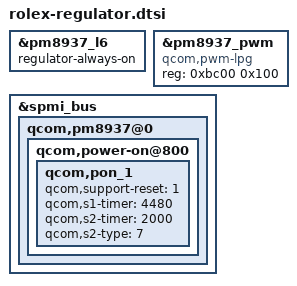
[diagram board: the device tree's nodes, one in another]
/*
 * Copyright (c) 2016, The Linux Foundation. All rights reserved.
 *
 * This program is free software; you can redistribute it and/or modify
 * it under the terms of the GNU General Public License version 2 and
 * only version 2 as published by the Free Software Foundation.
 *
 * This program is distributed in the hope that it will be useful,
 * but WITHOUT ANY WARRANTY; without even the implied warranty of
 * MERCHANTABILITY or FITNESS FOR A PARTICULAR PURPOSE.  See the
 * GNU General Public License for more details.
 */

/* msm8917-pmi8937-qrd-sku5 */
&pm8937_l6 {
	regulator-always-on;
};

&pm8937_pwm {
	status = "ok";
	compatible = "qcom,pwm-lpg";
	reg = <0xbc00 0x100>;
	reg-names = "lpg-base";
	#pwm-cells = <2>;
};

/* pm8937 */
&spmi_bus {
    qcom,pm8937@0 {
        qcom,power-on@800 {
            qcom,pon_1 {
            	qcom,support-reset = <1>;
				qcom,s1-timer = <4480>;
				qcom,s2-timer = <2000>;
				qcom,s2-type = <7>;
            };
        };
    };
};
